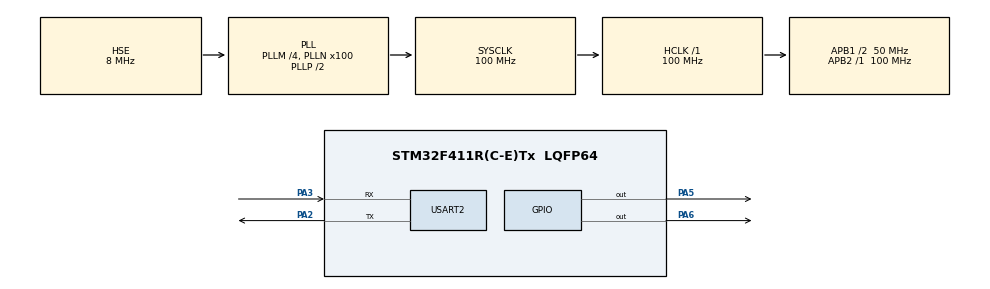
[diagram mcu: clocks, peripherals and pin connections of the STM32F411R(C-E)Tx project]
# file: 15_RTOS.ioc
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FREERTOS.Tasks01=LED_TASK_1,24,128,LED_TASK_01,Default,NULL,Dynamic,NULL,NULL;LED_TASK_2,24,128,LED_TASK_02,Default,NULL,Dynamic,NULL,NULL
FREERTOS.configUSE_NEWLIB_REENTRANT=1
Mcu.Family=STM32F4
Mcu.Name=STM32F411R(C-E)Tx
Mcu.Package=LQFP64
NVIC.PriorityGroup=NVIC_PRIORITYGROUP_4
NVIC.TIM1_UP_TIM10_IRQn=true\:15\:0\:false\:false\:true\:false\:false\:true\:true
NVIC.TimeBase=TIM1_UP_TIM10_IRQn
NVIC.TimeBaseIP=TIM10
PA13.Mode=Serial_Wire
PA13.Signal=SYS_JTMS-SWDIO
PA14.Mode=Serial_Wire
PA14.Signal=SYS_JTCK-SWCLK
PA2.Mode=Asynchronous
PA2.Signal=USART2_TX
PA3.Mode=Asynchronous
PA3.Signal=USART2_RX
PA5.Signal=GPIO_Output
PA6.Signal=GPIO_Output
PH0\ -\ OSC_IN.Mode=HSE-External-Oscillator
PH0\ -\ OSC_IN.Signal=RCC_OSC_IN
PH1\ -\ OSC_OUT.Mode=HSE-External-Oscillator
PH1\ -\ OSC_OUT.Signal=RCC_OSC_OUT
ProjectManager.HeapSize=0x200
ProjectManager.StackSize=0x400
ProjectManager.TargetToolchain=STM32CubeIDE
RCC.48MHZClocksFreq_Value=50000000
RCC.AHBFreq_Value=100000000
RCC.APB1CLKDivider=RCC_HCLK_DIV2
RCC.APB1Freq_Value=50000000
RCC.APB1TimFreq_Value=100000000
RCC.APB2Freq_Value=100000000
RCC.APB2TimFreq_Value=100000000
RCC.CortexFreq_Value=100000000
RCC.HCLKFreq_Value=100000000
RCC.HSE_VALUE=8000000
RCC.HSI_VALUE=16000000
RCC.LSE_VALUE=32768
RCC.PLLM=4
RCC.PLLN=100
RCC.PLLSourceVirtual=RCC_PLLSOURCE_HSE
RCC.SYSCLKFreq_VALUE=100000000
RCC.SYSCLKSource=RCC_SYSCLKSOURCE_PLLCLK
RCC.VCOOutputFreq_Value=200000000
USART2.VirtualMode=VM_ASYNC
VP_FREERTOS_VS_CMSIS_V2.Mode=CMSIS_V2
VP_SYS_VS_tim10.Mode=TIM10
board=custom

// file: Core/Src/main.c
/* USER CODE BEGIN Header */
/**
  ******************************************************************************
  * @file           : main.c
  * @brief          : Main program body
  ******************************************************************************
  * @attention
  *
  * Copyright (c) 2025 STMicroelectronics.
  * All rights reserved.
  *
  * This software is licensed under terms that can be found in the LICENSE file
  * in the root directory of this software component.
  * If no LICENSE file comes with this software, it is provided AS-IS.
  *
  ******************************************************************************
  */
/* USER CODE END Header */
#include "main.h"
#include "cmsis_os.h"
#include "usart.h"
#include "gpio.h"

void SystemClock_Config(void);
void MX_FREERTOS_Init(void);

int main(void)
{

  /* MCU Configuration--------------------------------------------------------*/

  /* Reset of all peripherals, Initializes the Flash interface and the Systick. */
  HAL_Init();

  /* Configure the system clock */
  SystemClock_Config();

  /* Initialize all configured peripherals */
  MX_GPIO_Init();
  MX_USART2_UART_Init();

  /* Init scheduler */
  osKernelInitialize();

  /* Call init function for freertos objects (in cmsis_os2.c) */
  MX_FREERTOS_Init();

  /* Start scheduler */
  osKernelStart();

  /* We should never get here as control is now taken by the scheduler */

  /* Infinite loop */
  /* USER CODE BEGIN WHILE */
  while (1)   // osKernelStart(); 실행되면 oskernel문 아래로 실행안되고 freertos.c의 Task로 가서 작동한다.(무한반복문)
  {
    /* USER CODE END WHILE */

  }
}

void SystemClock_Config(void)
{
  RCC_OscInitTypeDef RCC_OscInitStruct = {0};
  RCC_ClkInitTypeDef RCC_ClkInitStruct = {0};

  /** Configure the main internal regulator output voltage
  */
  __HAL_RCC_PWR_CLK_ENABLE();
  __HAL_PWR_VOLTAGESCALING_CONFIG(PWR_REGULATOR_VOLTAGE_SCALE1);

  /** Initializes the RCC Oscillators according to the specified parameters
  * in the RCC_OscInitTypeDef structure.
  */
  RCC_OscInitStruct.OscillatorType = RCC_OSCILLATORTYPE_HSE;
  RCC_OscInitStruct.HSEState = RCC_HSE_ON;
  RCC_OscInitStruct.PLL.PLLState = RCC_PLL_ON;
  RCC_OscInitStruct.PLL.PLLSource = RCC_PLLSOURCE_HSE;
  RCC_OscInitStruct.PLL.PLLM = 4;
  RCC_OscInitStruct.PLL.PLLN = 100;
  RCC_OscInitStruct.PLL.PLLP = RCC_PLLP_DIV2;
  RCC_OscInitStruct.PLL.PLLQ = 4;
  if (HAL_RCC_OscConfig(&RCC_OscInitStruct) != HAL_OK)
  {
    Error_Handler();
  }

  /** Initializes the CPU, AHB and APB buses clocks
  */
  RCC_ClkInitStruct.ClockType = RCC_CLOCKTYPE_HCLK|RCC_CLOCKTYPE_SYSCLK
                              |RCC_CLOCKTYPE_PCLK1|RCC_CLOCKTYPE_PCLK2;
  RCC_ClkInitStruct.SYSCLKSource = RCC_SYSCLKSOURCE_PLLCLK;
  RCC_ClkInitStruct.AHBCLKDivider = RCC_SYSCLK_DIV1;
  RCC_ClkInitStruct.APB1CLKDivider = RCC_HCLK_DIV2;
  RCC_ClkInitStruct.APB2CLKDivider = RCC_HCLK_DIV1;

  if (HAL_RCC_ClockConfig(&RCC_ClkInitStruct, FLASH_LATENCY_3) != HAL_OK)
  {
    Error_Handler();
  }
}

void HAL_TIM_PeriodElapsedCallback(TIM_HandleTypeDef *htim)
{
  if (htim->Instance == TIM10)
  {
    HAL_IncTick();
  }
}

void Error_Handler(void)
{
  __disable_irq();
  while (1)
  {
  }
}

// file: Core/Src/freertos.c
/* USER CODE BEGIN Header */
/**
  ******************************************************************************
  * File Name          : freertos.c
  * Description        : Code for freertos applications
  ******************************************************************************
  * @attention
  *
  * Copyright (c) 2025 STMicroelectronics.
  * All rights reserved.
  *
  * This software is licensed under terms that can be found in the LICENSE file
  * in the root directory of this software component.
  * If no LICENSE file comes with this software, it is provided AS-IS.
  *
  ******************************************************************************
  */
/* USER CODE END Header */

#include "FreeRTOS.h"
#include "task.h"
#include "main.h"
#include "cmsis_os.h"

/* Definitions for LED_TASK_1 */
osThreadId_t LED_TASK_1Handle;
const osThreadAttr_t LED_TASK_1_attributes = {
  .name = "LED_TASK_1",
  .stack_size = 128 * 4,
  .priority = (osPriority_t) osPriorityNormal,
};
/* Definitions for LED_TASK_2 */
osThreadId_t LED_TASK_2Handle;
const osThreadAttr_t LED_TASK_2_attributes = {
  .name = "LED_TASK_2",
  .stack_size = 128 * 4,
  .priority = (osPriority_t) osPriorityNormal,
};

void LED_TASK_01(void *argument);
void LED_TASK_02(void *argument);

void MX_FREERTOS_Init(void); /* (MISRA C 2004 rule 8.1) */

void MX_FREERTOS_Init(void) {

  /* Create the thread(s) */
  /* creation of LED_TASK_1 */
  LED_TASK_1Handle = osThreadNew(LED_TASK_01, NULL, &LED_TASK_1_attributes);

  /* creation of LED_TASK_2 */
  LED_TASK_2Handle = osThreadNew(LED_TASK_02, NULL, &LED_TASK_2_attributes);

}

void LED_TASK_01(void *argument)
{
  /* USER CODE BEGIN LED_TASK_01 */
  /* Infinite loop */
  for(;;)  // oskenel 이후 125 ~ 162줄 무한 반복
  {
    HAL_GPIO_WritePin(GPIOA, GPIO_PIN_5, GPIO_PIN_SET);
    osDelay(500);
    HAL_GPIO_WritePin(GPIOA, GPIO_PIN_5, GPIO_PIN_RESET);
    osDelay(500);

    osDelay(1);
  }
  /* USER CODE END LED_TASK_01 */
}

void LED_TASK_02(void *argument)
{
  /* USER CODE BEGIN LED_TASK_02 */
  /* Infinite loop */
  for(;;)
  {
    HAL_GPIO_WritePin(GPIOA, GPIO_PIN_6, GPIO_PIN_SET);
    osDelay(1000);
    HAL_GPIO_WritePin(GPIOA, GPIO_PIN_6, GPIO_PIN_RESET);
    osDelay(1000);

    osDelay(1);
  }
  /* USER CODE END LED_TASK_02 */
}
